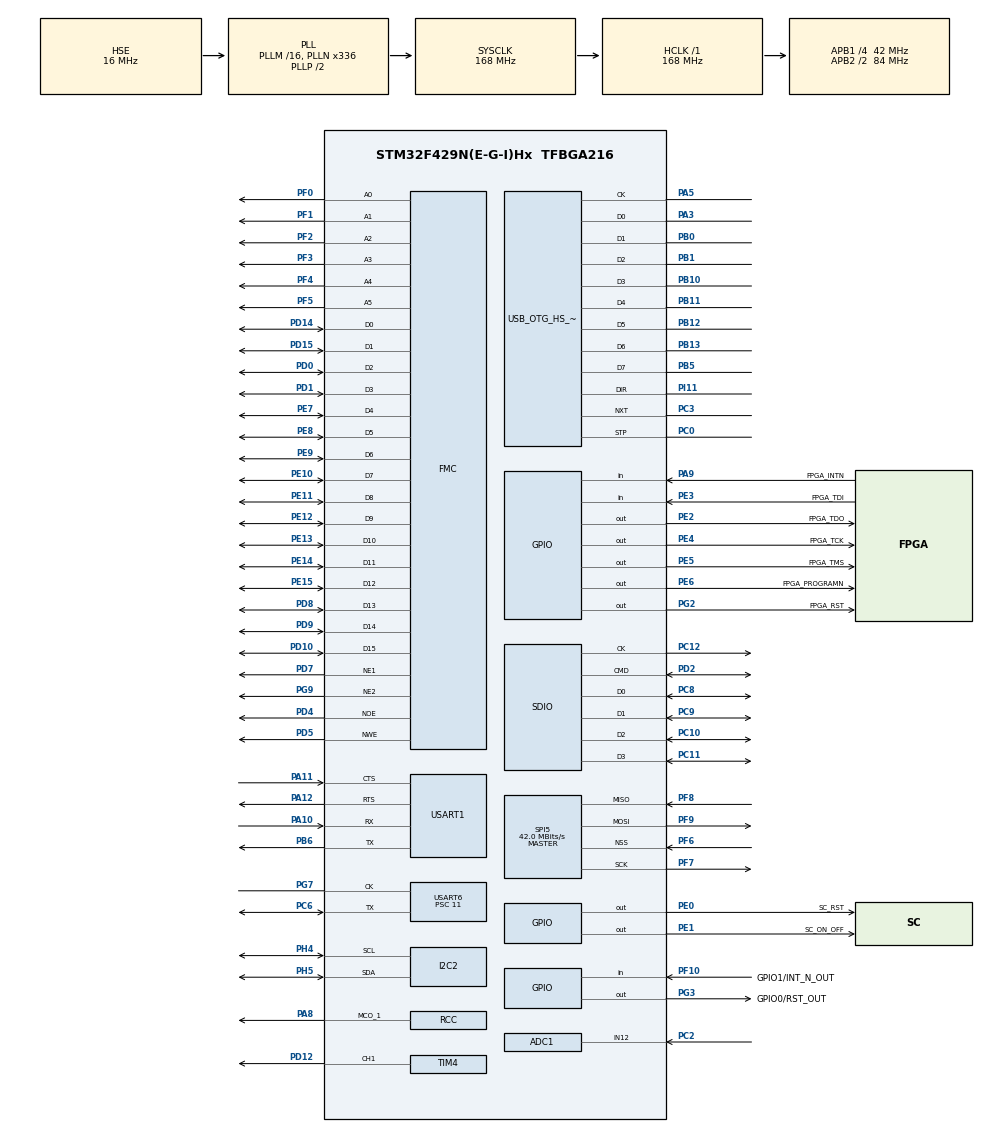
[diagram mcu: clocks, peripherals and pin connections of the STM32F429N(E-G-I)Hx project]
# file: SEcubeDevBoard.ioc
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ADC1.Channel-0\#ChannelRegularConversion=ADC_CHANNEL_12
ADC1.Rank-0\#ChannelRegularConversion=1
ADC1.SamplingTime-0\#ChannelRegularConversion=ADC_SAMPLETIME_3CYCLES
ADC1.master=1
Dma.Request0=SDIO_RX
Dma.Request1=SDIO_TX
Dma.SDIO_RX.0.Direction=DMA_PERIPH_TO_MEMORY
Dma.SDIO_RX.0.FIFOMode=DMA_FIFOMODE_ENABLE
Dma.SDIO_RX.0.FIFOThreshold=DMA_FIFO_THRESHOLD_FULL
Dma.SDIO_RX.0.Instance=DMA2_Stream3
Dma.SDIO_RX.0.MemBurst=DMA_MBURST_INC4
Dma.SDIO_RX.0.MemDataAlignment=DMA_MDATAALIGN_WORD
Dma.SDIO_RX.0.MemInc=DMA_MINC_ENABLE
Dma.SDIO_RX.0.Mode=DMA_PFCTRL
Dma.SDIO_RX.0.PeriphBurst=DMA_PBURST_INC4
Dma.SDIO_RX.0.PeriphDataAlignment=DMA_PDATAALIGN_WORD
Dma.SDIO_RX.0.PeriphInc=DMA_PINC_DISABLE
Dma.SDIO_RX.0.Priority=DMA_PRIORITY_VERY_HIGH
Dma.SDIO_TX.1.Direction=DMA_MEMORY_TO_PERIPH
Dma.SDIO_TX.1.FIFOMode=DMA_FIFOMODE_ENABLE
Dma.SDIO_TX.1.FIFOThreshold=DMA_FIFO_THRESHOLD_FULL
Dma.SDIO_TX.1.Instance=DMA2_Stream6
Dma.SDIO_TX.1.MemBurst=DMA_MBURST_INC4
Dma.SDIO_TX.1.MemDataAlignment=DMA_MDATAALIGN_WORD
Dma.SDIO_TX.1.MemInc=DMA_MINC_ENABLE
Dma.SDIO_TX.1.Mode=DMA_PFCTRL
Dma.SDIO_TX.1.PeriphBurst=DMA_PBURST_INC4
Dma.SDIO_TX.1.PeriphDataAlignment=DMA_PDATAALIGN_WORD
Dma.SDIO_TX.1.PeriphInc=DMA_PINC_DISABLE
Dma.SDIO_TX.1.Priority=DMA_PRIORITY_VERY_HIGH
Mcu.Family=STM32F4
Mcu.Name=STM32F429N(E-G-I)Hx
Mcu.Package=TFBGA216
NVIC.DMA2_Stream3_IRQn=true\:6\:0\:true\:false\:true\:true\:true
NVIC.DMA2_Stream6_IRQn=true\:6\:0\:true\:false\:true\:true\:true
NVIC.OTG_HS_IRQn=true\:7\:0\:true\:false\:true\:true\:true
NVIC.PriorityGroup=NVIC_PRIORITYGROUP_4
NVIC.SDIO_IRQn=true\:5\:0\:true\:false\:true\:true\:true
PA0/WKUP.Mode=SYS-WakeUp
PA0/WKUP.Signal=SYS_WKUP
PA10.Mode=Asynchronous
PA10.Signal=USART1_RX
PA11.Mode=CTS_RTS
PA11.Signal=USART1_CTS
PA12.Mode=CTS_RTS
PA12.Signal=USART1_RTS
PA13.Mode=JTAG(5-pin)
PA13.Signal=SYS_JTMS-SWDIO
PA14.Mode=JTAG(5-pin)
PA14.Signal=SYS_JTCK-SWCLK
PA15.Mode=JTAG(5-pin)
PA15.Signal=SYS_JTDI
PA3.Mode=Device_HS
PA3.Signal=USB_OTG_HS_ULPI_D0
PA5.Mode=Device_HS
PA5.Signal=USB_OTG_HS_ULPI_CK
PA8.Mode=Clock-out-1
PA8.Signal=RCC_MCO_1
PA9.GPIO_Label=FPGA_INTN
PA9.GPIO_Mode=GPIO_MODE_INPUT
PA9.GPIO_PuPd=GPIO_NOPULL
PA9.Signal=GPIO_Input
PB0.Mode=Device_HS
PB0.Signal=USB_OTG_HS_ULPI_D1
PB1.Mode=Device_HS
PB1.Signal=USB_OTG_HS_ULPI_D2
PB10.Mode=Device_HS
PB10.Signal=USB_OTG_HS_ULPI_D3
PB11.Mode=Device_HS
PB11.Signal=USB_OTG_HS_ULPI_D4
PB12.Mode=Device_HS
PB12.Signal=USB_OTG_HS_ULPI_D5
PB13.Mode=Device_HS
PB13.Signal=USB_OTG_HS_ULPI_D6
PB3.Mode=JTAG(5-pin)
PB3.Signal=SYS_JTDO-SWO
PB4.Mode=JTAG(5-pin)
PB4.Signal=SYS_JTRST
PB5.Mode=Device_HS
PB5.Signal=USB_OTG_HS_ULPI_D7
PB6.Mode=Asynchronous
PB6.Signal=USART1_TX
PC0.Mode=Device_HS
PC0.Signal=USB_OTG_HS_ULPI_STP
PC10.Mode=SD_4_bits_Wide_bus
PC10.Signal=SDIO_D2
PC11.Mode=SD_4_bits_Wide_bus
PC11.Signal=SDIO_D3
PC12.Mode=SD_4_bits_Wide_bus
PC12.Signal=SDIO_CK
PC2.Signal=ADCx_IN12
PC3.Mode=Device_HS
PC3.Signal=USB_OTG_HS_ULPI_NXT
PC6.Mode=SmartCard_With_Clock
PC6.Signal=USART6_TX
PC8.Mode=SD_4_bits_Wide_bus
PC8.Signal=SDIO_D0
PC9.Mode=SD_4_bits_Wide_bus
PC9.Signal=SDIO_D1
PD0.Signal=FMC_D2_DA2
PD1.Signal=FMC_D3_DA3
PD10.Signal=FMC_D15_DA15
PD12.Signal=S_TIM4_CH1
PD14.Signal=FMC_D0_DA0
PD15.Signal=FMC_D1_DA1
PD2.Mode=SD_4_bits_Wide_bus
PD2.Signal=SDIO_CMD
PD4.Signal=FMC_NOE
PD5.Signal=FMC_NWE
PD7.Mode=NorPsramChipSelect1_1
PD7.Signal=FMC_NE1
PD8.Signal=FMC_D13_DA13
PD9.Signal=FMC_D14_DA14
PE0.GPIO_Label=SC_RST
PE0.GPIO_ModeDefaultOutputPP=GPIO_MODE_OUTPUT_PP
PE0.GPIO_PuPd=GPIO_NOPULL
PE0.GPIO_Speed=GPIO_SPEED_LOW
PE0.Signal=GPIO_Output
PE1.GPIO_Label=SC_ON_OFF
PE1.GPIO_ModeDefaultOutputPP=GPIO_MODE_OUTPUT_PP
PE1.GPIO_PuPd=GPIO_NOPULL
PE1.GPIO_Speed=GPIO_SPEED_LOW
PE1.Signal=GPIO_Output
PE10.Signal=FMC_D7_DA7
PE11.Signal=FMC_D8_DA8
PE12.Signal=FMC_D9_DA9
PE13.Signal=FMC_D10_DA10
PE14.Signal=FMC_D11_DA11
PE15.Signal=FMC_D12_DA12
PE2.GPIO_Label=FPGA_TDO
PE2.GPIO_ModeDefaultOutputPP=GPIO_MODE_OUTPUT_PP
PE2.GPIO_PuPd=GPIO_NOPULL
PE2.GPIO_Speed=GPIO_SPEED_LOW
PE2.Signal=GPIO_Output
PE3.GPIO_Label=FPGA_TDI
PE3.GPIO_Mode=GPIO_MODE_INPUT
PE3.GPIO_PuPd=GPIO_NOPULL
PE3.Signal=GPIO_Input
PE4.GPIO_Label=FPGA_TCK
PE4.GPIO_ModeDefaultOutputPP=GPIO_MODE_OUTPUT_PP
PE4.GPIO_PuPd=GPIO_NOPULL
PE4.GPIO_Speed=GPIO_SPEED_LOW
PE4.Signal=GPIO_Output
PE5.GPIO_Label=FPGA_TMS
PE5.GPIO_ModeDefaultOutputPP=GPIO_MODE_OUTPUT_PP
PE5.GPIO_PuPd=GPIO_NOPULL
PE5.GPIO_Speed=GPIO_SPEED_LOW
PE5.Signal=GPIO_Output
PE6.GPIO_Label=FPGA_PROGRAMN
PE6.GPIO_ModeDefaultOutputPP=GPIO_MODE_OUTPUT_PP
PE6.GPIO_PuPd=GPIO_NOPULL
PE6.GPIO_Speed=GPIO_SPEED_LOW
PE6.Signal=GPIO_Output
PE7.Signal=FMC_D4_DA4
PE8.Signal=FMC_D5_DA5
PE9.Signal=FMC_D6_DA6
PF0.Signal=FMC_A0
PF1.Signal=FMC_A1
PF10.GPIO_Label=GPIO1/INT_N_OUT
PF10.GPIO_Mode=GPIO_MODE_INPUT
PF10.GPIO_PuPd=GPIO_NOPULL
PF10.Signal=GPIO_Input
PF2.Signal=FMC_A2
PF3.Signal=FMC_A3
PF4.Signal=FMC_A4
PF5.Signal=FMC_A5
PF6.Mode=NSS_Signal_Hard_Input
PF6.Signal=SPI5_NSS
PF7.Mode=Full_Duplex_Master
PF7.Signal=SPI5_SCK
PF8.Mode=Full_Duplex_Master
PF8.Signal=SPI5_MISO
PF9.Mode=Full_Duplex_Master
PF9.Signal=SPI5_MOSI
PG2.GPIO_Label=FPGA_RST
PG2.GPIO_ModeDefaultOutputPP=GPIO_MODE_OUTPUT_PP
PG2.GPIO_PuPd=GPIO_NOPULL
PG2.GPIO_Speed=GPIO_SPEED_LOW
PG2.Signal=GPIO_Output
PG3.GPIO_Label=GPIO0/RST_OUT
PG3.GPIO_ModeDefaultOutputPP=GPIO_MODE_OUTPUT_PP
PG3.GPIO_PuPd=GPIO_NOPULL
PG3.GPIO_Speed=GPIO_SPEED_LOW
PG3.Signal=GPIO_Output
PG7.Mode=SmartCard_With_Clock
PG7.Signal=USART6_CK
PG9.Mode=NorPsramChipSelect2_2
PG9.Signal=FMC_NE2
PH0/OSC_IN.Mode=HSE-External-Oscillator
PH0/OSC_IN.Signal=RCC_OSC_IN
PH1/OSC_OUT.Mode=HSE-External-Oscillator
PH1/OSC_OUT.Signal=RCC_OSC_OUT
PH4.Mode=I2C
PH4.Signal=I2C2_SCL
PH5.Mode=I2C
PH5.Signal=I2C2_SDA
PI11.Mode=Device_HS
PI11.Signal=USB_OTG_HS_ULPI_DIR
ProjectManager.HeapSize=0x400
ProjectManager.StackSize=0x200
ProjectManager.TargetToolchain=STM32CubeIDE
RCC.48MHZClocksFreq_Value=48000000
RCC.AHBFreq_Value=168000000
RCC.APB1CLKDivider=RCC_HCLK_DIV4
RCC.APB1Freq_Value=42000000
RCC.APB1TimFreq_Value=84000000
RCC.APB2CLKDivider=RCC_HCLK_DIV2
RCC.APB2Freq_Value=84000000
RCC.APB2TimFreq_Value=168000000
RCC.CortexFreq_Value=168000000
RCC.HCLKFreq_Value=168000000
RCC.HSE_VALUE=16000000
RCC.HSI_VALUE=16000000
RCC.LSE_VALUE=32768
RCC.PLLN=336
RCC.PLLQ=7
RCC.PLLSourceVirtual=RCC_PLLSOURCE_HSE
RCC.RCC_MCO1Source=RCC_MCO1SOURCE_PLLCLK
RCC.RCC_MCODiv1=RCC_MCODIV_2
RCC.SYSCLKFreq_VALUE=168000000
RCC.SYSCLKSource=RCC_SYSCLKSOURCE_PLLCLK
RCC.VCOOutputFreq_Value=336000000
SDIO.BusWide-SD_4_bits_Wide_bus=SDIO_BUS_WIDE_1B
SH.ADCx_IN12.0=ADC1_IN12,IN12
SH.FMC_A0.0=FMC_A0,6b-a2
SH.FMC_A0.1=FMC_A0,6b-a1
SH.FMC_A1.0=FMC_A1,6b-a2
SH.FMC_A1.1=FMC_A1,6b-a1
SH.FMC_A2.0=FMC_A2,6b-a2
SH.FMC_A2.1=FMC_A2,6b-a1
SH.FMC_A3.0=FMC_A3,6b-a2
SH.FMC_A3.1=FMC_A3,6b-a1
SH.FMC_A4.0=FMC_A4,6b-a2
SH.FMC_A4.1=FMC_A4,6b-a1
SH.FMC_A5.0=FMC_A5,6b-a2
SH.FMC_A5.1=FMC_A5,6b-a1
SH.FMC_D0_DA0.0=FMC_D0,16b-d1
SH.FMC_D0_DA0.1=FMC_D0,16b-d2
SH.FMC_D10_DA10.0=FMC_D10,16b-d1
SH.FMC_D10_DA10.1=FMC_D10,16b-d2
SH.FMC_D11_DA11.0=FMC_D11,16b-d1
SH.FMC_D11_DA11.1=FMC_D11,16b-d2
SH.FMC_D12_DA12.0=FMC_D12,16b-d1
SH.FMC_D12_DA12.1=FMC_D12,16b-d2
SH.FMC_D13_DA13.0=FMC_D13,16b-d1
SH.FMC_D13_DA13.1=FMC_D13,16b-d2
SH.FMC_D14_DA14.0=FMC_D14,16b-d1
SH.FMC_D14_DA14.1=FMC_D14,16b-d2
SH.FMC_D15_DA15.0=FMC_D15,16b-d1
SH.FMC_D15_DA15.1=FMC_D15,16b-d2
SH.FMC_D1_DA1.0=FMC_D1,16b-d1
SH.FMC_D1_DA1.1=FMC_D1,16b-d2
SH.FMC_D2_DA2.0=FMC_D2,16b-d1
SH.FMC_D2_DA2.1=FMC_D2,16b-d2
SH.FMC_D3_DA3.0=FMC_D3,16b-d1
SH.FMC_D3_DA3.1=FMC_D3,16b-d2
SH.FMC_D4_DA4.0=FMC_D4,16b-d1
SH.FMC_D4_DA4.1=FMC_D4,16b-d2
SH.FMC_D5_DA5.0=FMC_D5,16b-d1
SH.FMC_D5_DA5.1=FMC_D5,16b-d2
SH.FMC_D6_DA6.0=FMC_D6,16b-d1
SH.FMC_D6_DA6.1=FMC_D6,16b-d2
SH.FMC_D7_DA7.0=FMC_D7,16b-d1
SH.FMC_D7_DA7.1=FMC_D7,16b-d2
SH.FMC_D8_DA8.0=FMC_D8,16b-d1
SH.FMC_D8_DA8.1=FMC_D8,16b-d2
SH.FMC_D9_DA9.0=FMC_D9,16b-d1
SH.FMC_D9_DA9.1=FMC_D9,16b-d2
SH.FMC_NOE.0=FMC_NOE,NorFlash1
SH.FMC_NOE.1=FMC_NOE,NorFlash2
SH.FMC_NWE.0=FMC_NWE,NorFlash1
SH.FMC_NWE.1=FMC_NWE,NorFlash2
SH.S_TIM4_CH1.0=TIM4_CH1,PWM Generation1 CH1
SPI5.BaudRatePrescaler=SPI_BAUDRATEPRESCALER_2
SPI5.BaudRatePrescaler-Full_Duplex_Master=SPI_BAUDRATEPRESCALER_2
SPI5.CalculateBaudRate=42.0 MBits/s
SPI5.CalculateBaudRate-Full_Duplex_Master=45.0 MBits/s
SPI5.Direction=SPI_DIRECTION_2LINES
SPI5.Mode=SPI_MODE_MASTER
SPI5.Mode-Full_Duplex_Master=SPI_MODE_MASTER
SPI5.VirtualNSS=VM_NSSHARD
SPI5.VirtualType=VM_MASTER
TIM4.Channel-PWM\ Generation1\ CH1=TIM_CHANNEL_1
USART1.VirtualMode=VM_ASYNC
USART6.CalculateSpeed=3.818181 MHz
USART6.Prescaler=11
USART6.VirtualClockMode=VM_SMARTCARD
USART6.VirtualMode=VM_SMARTCARD
USART6.VirtualMode-SmartCard_With_Clock=VM_SMARTCARD
USB_DEVICE.MANUFACTURER_STRING-MSC_HS=Pascal
USB_DEVICE.MSC_MEDIA_PACKET-MSC_HS=16384
USB_DEVICE.PRODUCT_STRING_MSC_HS=SEcubeDevBoardv0.01
USB_DEVICE.USBD_HandleTypeDef-MSC_HS=hUsbDeviceHS
USB_DEVICE.VirtualMode-MSC_HS=Msc
USB_DEVICE.VirtualModeHS=Msc_HS
USB_OTG_HS.VirtualMode-Device_HS=Device_HS
USB_OTG_HS.dma_enable-Device_HS=ENABLE
USB_OTG_HS.vbus_sensing_enable-Device_HS=ENABLE
VP_CRC_VS_CRC.Mode=CRC_Activate
VP_RNG_VS_RNG.Mode=RNG_Activate
VP_USB_DEVICE_VS_USB_DEVICE_MSC_HS.Mode=MSC_HS
board=SEcubeDevBoard

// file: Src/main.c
/**
  ******************************************************************************
  * File Name          : main.c
  * Description        : Main program body
  ******************************************************************************
  *
  * COPYRIGHT(c) 2021 STMicroelectronics
  *
  * Redistribution and use in source and binary forms, with or without modification,
  * are permitted provided that the following conditions are met:
  *   1. Redistributions of source code must retain the above copyright notice,
  *      this list of conditions and the following disclaimer.
  *   2. Redistributions in binary form must reproduce the above copyright notice,
  *      this list of conditions and the following disclaimer in the documentation
  *      and/or other materials provided with the distribution.
  *   3. Neither the name of STMicroelectronics nor the names of its contributors
  *      may be used to endorse or promote products derived from this software
  *      without specific prior written permission.
  *
  * THIS SOFTWARE IS PROVIDED BY THE COPYRIGHT HOLDERS AND CONTRIBUTORS "AS IS"
  * AND ANY EXPRESS OR IMPLIED WARRANTIES, INCLUDING, BUT NOT LIMITED TO, THE
  * IMPLIED WARRANTIES OF MERCHANTABILITY AND FITNESS FOR A PARTICULAR PURPOSE ARE
  * DISCLAIMED. IN NO EVENT SHALL THE COPYRIGHT HOLDER OR CONTRIBUTORS BE LIABLE
  * FOR ANY DIRECT, INDIRECT, INCIDENTAL, SPECIAL, EXEMPLARY, OR CONSEQUENTIAL
  * DAMAGES (INCLUDING, BUT NOT LIMITED TO, PROCUREMENT OF SUBSTITUTE GOODS OR
  * SERVICES; LOSS OF USE, DATA, OR PROFITS; OR BUSINESS INTERRUPTION) HOWEVER
  * CAUSED AND ON ANY THEORY OF LIABILITY, WHETHER IN CONTRACT, STRICT LIABILITY,
  * OR TORT (INCLUDING NEGLIGENCE OR OTHERWISE) ARISING IN ANY WAY OUT OF THE USE
  * OF THIS SOFTWARE, EVEN IF ADVISED OF THE POSSIBILITY OF SUCH DAMAGE.
  *
  ******************************************************************************
  */
#include "stm32f4xx_hal.h"
#include "adc.h"
#include "crc.h"
#include "dma.h"
#include "i2c.h"
#include "rng.h"
#include "sdio.h"
#include "spi.h"
#include "tim.h"
#include "usart.h"
#include "usb_device.h"
#include "gpio.h"
#include "fmc.h"

/* USER CODE BEGIN Includes */
#include "se3_sekey.h"
#include "se3_core.h"

/* USER CODE END Includes */

/* USER CODE BEGIN PV */
/* Private variables ---------------------------------------------------------*/

/* USER CODE END PV */

void SystemClock_Config(void);

/* USER CODE BEGIN PFP */
/* Private function prototypes -----------------------------------------------*/

/* USER CODE END PFP */

int main(void)
{

  /* MCU Configuration----------------------------------------------------------*/

  /* Reset of all peripherals, Initializes the Flash interface and the Systick. */
  HAL_Init();

  /* Configure the system clock */
  SystemClock_Config();

  /* Initialize all configured peripherals */
  MX_GPIO_Init();
  MX_DMA_Init();
  SystemClock_Config();
  MX_ADC1_Init();
  MX_CRC_Init();
  MX_FMC_Init();
  MX_I2C2_Init();
  MX_RNG_Init();
  MX_SDIO_SD_Init();
  MX_SPI5_Init();
  MX_TIM4_Init();
  MX_USART1_UART_Init();
  MX_USART6_SMARTCARD_Init();
  MX_USB_DEVICE_Init();

	/* USER CODE BEGIN */
	device_init();

	device_loop();
	/* USER CODE END  */

	return 0;

}

/** System Clock Configuration
*/
void SystemClock_Config(void)
{

  RCC_OscInitTypeDef RCC_OscInitStruct;
  RCC_ClkInitTypeDef RCC_ClkInitStruct;

  __PWR_CLK_ENABLE();

  __HAL_PWR_VOLTAGESCALING_CONFIG(PWR_REGULATOR_VOLTAGE_SCALE1);

  RCC_OscInitStruct.OscillatorType = RCC_OSCILLATORTYPE_HSE;
  RCC_OscInitStruct.HSEState = RCC_HSE_ON;
  RCC_OscInitStruct.PLL.PLLState = RCC_PLL_ON;
  RCC_OscInitStruct.PLL.PLLSource = RCC_PLLSOURCE_HSE;
  RCC_OscInitStruct.PLL.PLLM = 16;
  RCC_OscInitStruct.PLL.PLLN = 336;
  RCC_OscInitStruct.PLL.PLLP = RCC_PLLP_DIV2;
  RCC_OscInitStruct.PLL.PLLQ = 7;
  HAL_RCC_OscConfig(&RCC_OscInitStruct);

  RCC_ClkInitStruct.ClockType = RCC_CLOCKTYPE_HCLK|RCC_CLOCKTYPE_SYSCLK
                              |RCC_CLOCKTYPE_PCLK1|RCC_CLOCKTYPE_PCLK2;
  RCC_ClkInitStruct.SYSCLKSource = RCC_SYSCLKSOURCE_PLLCLK;
  RCC_ClkInitStruct.AHBCLKDivider = RCC_SYSCLK_DIV1;
  RCC_ClkInitStruct.APB1CLKDivider = RCC_HCLK_DIV4;
  RCC_ClkInitStruct.APB2CLKDivider = RCC_HCLK_DIV2;
  HAL_RCC_ClockConfig(&RCC_ClkInitStruct, FLASH_LATENCY_5);

  HAL_RCC_MCOConfig(RCC_MCO1, RCC_MCO1SOURCE_PLLCLK, RCC_MCODIV_2);

  HAL_SYSTICK_Config(HAL_RCC_GetHCLKFreq()/1000);

  HAL_SYSTICK_CLKSourceConfig(SYSTICK_CLKSOURCE_HCLK);

  /* SysTick_IRQn interrupt configuration */
  HAL_NVIC_SetPriority(SysTick_IRQn, 0, 0);
}

/************************ (C) COPYRIGHT STMicroelectronics *****END OF FILE****/
